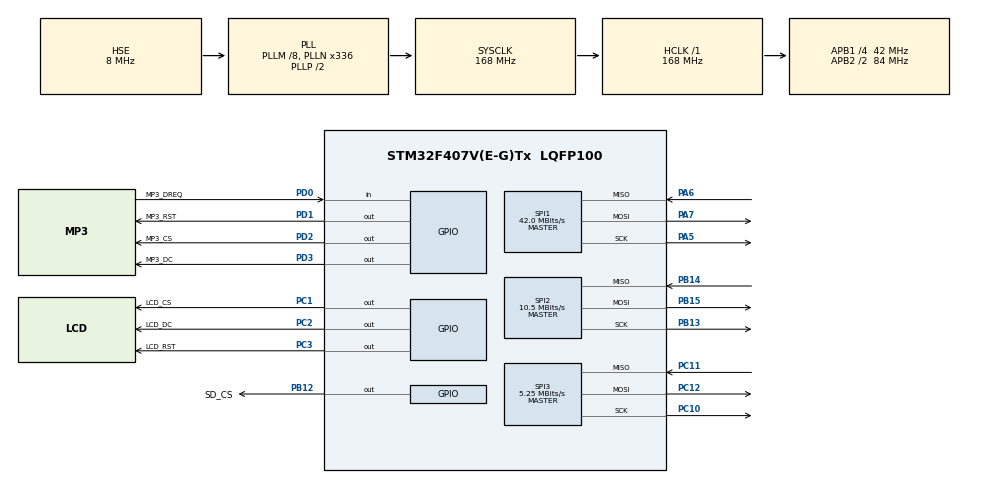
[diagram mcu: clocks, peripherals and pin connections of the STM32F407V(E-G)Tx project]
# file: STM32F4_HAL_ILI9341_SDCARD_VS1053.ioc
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Dma.Request0=SPI1_TX
Dma.SPI1_TX.0.Direction=DMA_MEMORY_TO_PERIPH
Dma.SPI1_TX.0.FIFOMode=DMA_FIFOMODE_DISABLE
Dma.SPI1_TX.0.Instance=DMA2_Stream3
Dma.SPI1_TX.0.MemDataAlignment=DMA_MDATAALIGN_BYTE
Dma.SPI1_TX.0.MemInc=DMA_MINC_ENABLE
Dma.SPI1_TX.0.Mode=DMA_NORMAL
Dma.SPI1_TX.0.PeriphDataAlignment=DMA_PDATAALIGN_BYTE
Dma.SPI1_TX.0.PeriphInc=DMA_PINC_DISABLE
Dma.SPI1_TX.0.Priority=DMA_PRIORITY_LOW
FATFS._CODE_PAGE=949
FATFS._MAX_SS=4096
FATFS._USE_LFN=1
Mcu.Family=STM32F4
Mcu.Name=STM32F407V(E-G)Tx
Mcu.Package=LQFP100
NVIC.DMA2_Stream3_IRQn=true\:0\:0\:false\:false\:true\:false
NVIC.PriorityGroup=NVIC_PRIORITYGROUP_0
NVIC.SPI1_IRQn=true\:0\:0\:false\:false\:true\:true
PA5.Mode=Full_Duplex_Master
PA5.Signal=SPI1_SCK
PA6.Mode=Full_Duplex_Master
PA6.Signal=SPI1_MISO
PA7.Mode=Full_Duplex_Master
PA7.Signal=SPI1_MOSI
PB12.GPIO_Label=SD_CS
PB12.Signal=GPIO_Output
PB13.Mode=Full_Duplex_Master
PB13.Signal=SPI2_SCK
PB14.Mode=Full_Duplex_Master
PB14.Signal=SPI2_MISO
PB15.Mode=Full_Duplex_Master
PB15.Signal=SPI2_MOSI
PC1.GPIO_Label=LCD_CS
PC1.PinState=GPIO_PIN_RESET
PC1.Signal=GPIO_Output
PC10.Mode=Full_Duplex_Master
PC10.Signal=SPI3_SCK
PC11.Mode=Full_Duplex_Master
PC11.Signal=SPI3_MISO
PC12.Mode=Full_Duplex_Master
PC12.Signal=SPI3_MOSI
PC2.GPIO_Label=LCD_DC
PC2.Signal=GPIO_Output
PC3.GPIO_Label=LCD_RST
PC3.Signal=GPIO_Output
PD0.GPIO_Label=MP3_DREQ
PD0.GPIO_PuPd=GPIO_NOPULL
PD0.Signal=GPIO_Input
PD1.GPIO_Label=MP3_RST
PD1.Signal=GPIO_Output
PD2.GPIO_Label=MP3_CS
PD2.Signal=GPIO_Output
PD3.GPIO_Label=MP3_DC
PD3.Signal=GPIO_Output
PH0-OSC_IN.Mode=HSE-External-Oscillator
PH0-OSC_IN.Signal=RCC_OSC_IN
PH1-OSC_OUT.Mode=HSE-External-Oscillator
PH1-OSC_OUT.Signal=RCC_OSC_OUT
ProjectManager.HeapSize=0x200
ProjectManager.StackSize=0x800
ProjectManager.TargetToolchain=TrueSTUDIO
RCC.48MHZClocksFreq_Value=48000000
RCC.AHBFreq_Value=168000000
RCC.APB1CLKDivider=RCC_HCLK_DIV4
RCC.APB1Freq_Value=42000000
RCC.APB1TimFreq_Value=84000000
RCC.APB2CLKDivider=RCC_HCLK_DIV2
RCC.APB2Freq_Value=84000000
RCC.APB2TimFreq_Value=168000000
RCC.CortexFreq_Value=168000000
RCC.HCLKFreq_Value=168000000
RCC.HSE_VALUE=8000000
RCC.HSI_VALUE=16000000
RCC.LSE_VALUE=32768
RCC.PLLM=8
RCC.PLLN=336
RCC.PLLQ=7
RCC.PLLSourceVirtual=RCC_PLLSOURCE_HSE
RCC.SYSCLKFreq_VALUE=168000000
RCC.SYSCLKSource=RCC_SYSCLKSOURCE_PLLCLK
RCC.VCOOutputFreq_Value=336000000
SPI1.CalculateBaudRate=42.0 MBits/s
SPI1.Direction=SPI_DIRECTION_2LINES
SPI1.Mode=SPI_MODE_MASTER
SPI1.VirtualType=VM_MASTER
SPI2.BaudRatePrescaler=SPI_BAUDRATEPRESCALER_4
SPI2.CalculateBaudRate=10.5 MBits/s
SPI2.Direction=SPI_DIRECTION_2LINES
SPI2.Mode=SPI_MODE_MASTER
SPI2.VirtualType=VM_MASTER
SPI3.BaudRatePrescaler=SPI_BAUDRATEPRESCALER_8
SPI3.CalculateBaudRate=5.25 MBits/s
SPI3.Direction=SPI_DIRECTION_2LINES
SPI3.Mode=SPI_MODE_MASTER
SPI3.VirtualType=VM_MASTER
VP_FATFS_VS_Generic.Mode=User_defined
board=STM32F4DISCOVERY

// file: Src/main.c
/**
  ******************************************************************************
  * @file           : main.c
  * @brief          : Main program body
  ******************************************************************************
  * This notice applies to any and all portions of this file
  * that are not between comment pairs USER CODE BEGIN and
  * USER CODE END. Other portions of this file, whether
  * inserted by the user or by software development tools
  * are owned by their respective copyright owners.
  *
  * Copyright (c) 2019 STMicroelectronics International N.V.
  * All rights reserved.
  *
  * Redistribution and use in source and binary forms, with or without
  * modification, are permitted, provided that the following conditions are met:
  *
  * 1. Redistribution of source code must retain the above copyright notice,
  *    this list of conditions and the following disclaimer.
  * 2. Redistributions in binary form must reproduce the above copyright notice,
  *    this list of conditions and the following disclaimer in the documentation
  *    and/or other materials provided with the distribution.
  * 3. Neither the name of STMicroelectronics nor the names of other
  *    contributors to this software may be used to endorse or promote products
  *    derived from this software without specific written permission.
  * 4. This software, including modifications and/or derivative works of this
  *    software, must execute solely and exclusively on microcontroller or
  *    microprocessor devices manufactured by or for STMicroelectronics.
  * 5. Redistribution and use of this software other than as permitted under
  *    this license is void and will automatically terminate your rights under
  *    this license.
  *
  * THIS SOFTWARE IS PROVIDED BY STMICROELECTRONICS AND CONTRIBUTORS "AS IS"
  * AND ANY EXPRESS, IMPLIED OR STATUTORY WARRANTIES, INCLUDING, BUT NOT
  * LIMITED TO, THE IMPLIED WARRANTIES OF MERCHANTABILITY, FITNESS FOR A
  * PARTICULAR PURPOSE AND NON-INFRINGEMENT OF THIRD PARTY INTELLECTUAL PROPERTY
  * RIGHTS ARE DISCLAIMED TO THE FULLEST EXTENT PERMITTED BY LAW. IN NO EVENT
  * SHALL STMICROELECTRONICS OR CONTRIBUTORS BE LIABLE FOR ANY DIRECT, INDIRECT,
  * INCIDENTAL, SPECIAL, EXEMPLARY, OR CONSEQUENTIAL DAMAGES (INCLUDING, BUT NOT
  * LIMITED TO, PROCUREMENT OF SUBSTITUTE GOODS OR SERVICES; LOSS OF USE, DATA,
  * OR PROFITS; OR BUSINESS INTERRUPTION) HOWEVER CAUSED AND ON ANY THEORY OF
  * LIABILITY, WHETHER IN CONTRACT, STRICT LIABILITY, OR TORT (INCLUDING
  * NEGLIGENCE OR OTHERWISE) ARISING IN ANY WAY OUT OF THE USE OF THIS SOFTWARE,
  * EVEN IF ADVISED OF THE POSSIBILITY OF SUCH DAMAGE.
  *
  ******************************************************************************
  */
#include "main.h"
#include "stm32f4xx_hal.h"
#include "fatfs.h"

/* USER CODE BEGIN Includes */
#include "ILI9341_STM32_Driver.h"
#include "ILI9341_GFX.h"
#include "MP3_Player.h"

/* USER CODE END Includes */

SPI_HandleTypeDef hspi1;
SPI_HandleTypeDef hspi2;
SPI_HandleTypeDef hspi3;
DMA_HandleTypeDef hdma_spi1_tx;

/* USER CODE BEGIN PV */
/* Private variables ---------------------------------------------------------*/

/* USER CODE END PV */

void SystemClock_Config(void);
static void MX_GPIO_Init(void);
static void MX_DMA_Init(void);
static void MX_SPI1_Init(void);
static void MX_SPI2_Init(void);
static void MX_SPI3_Init(void);

/* USER CODE BEGIN PFP */
/* Private function prototypes -----------------------------------------------*/

/* USER CODE END PFP */

int main(void)
{

  /* MCU Configuration----------------------------------------------------------*/

  /* Reset of all peripherals, Initializes the Flash interface and the Systick. */
  HAL_Init();

  /* Configure the system clock */
  SystemClock_Config();

  /* Initialize all configured peripherals */
  MX_GPIO_Init();
  MX_DMA_Init();
  MX_SPI1_Init();
  MX_SPI2_Init();
  MX_FATFS_Init();
  MX_SPI3_Init();
  /* USER CODE BEGIN 2 */
	/* Wait time to power up */
	ILI9341_Init();
	ILI9341_FillScreen(WHITE);
	ILI9341_SetRotation(SCREEN_HORIZONTAL_2);

	MP3_Init();
	MP3_Play("track001.mp3");

  /* USER CODE END 2 */

  /* Infinite loop */
	while (1)
	{

	}

}

void SystemClock_Config(void)
{

  RCC_OscInitTypeDef RCC_OscInitStruct;
  RCC_ClkInitTypeDef RCC_ClkInitStruct;

    /**Configure the main internal regulator output voltage
    */
  __HAL_RCC_PWR_CLK_ENABLE();

  __HAL_PWR_VOLTAGESCALING_CONFIG(PWR_REGULATOR_VOLTAGE_SCALE1);

    /**Initializes the CPU, AHB and APB busses clocks
    */
  RCC_OscInitStruct.OscillatorType = RCC_OSCILLATORTYPE_HSE;
  RCC_OscInitStruct.HSEState = RCC_HSE_ON;
  RCC_OscInitStruct.PLL.PLLState = RCC_PLL_ON;
  RCC_OscInitStruct.PLL.PLLSource = RCC_PLLSOURCE_HSE;
  RCC_OscInitStruct.PLL.PLLM = 8;
  RCC_OscInitStruct.PLL.PLLN = 336;
  RCC_OscInitStruct.PLL.PLLP = RCC_PLLP_DIV2;
  RCC_OscInitStruct.PLL.PLLQ = 7;
  if (HAL_RCC_OscConfig(&RCC_OscInitStruct) != HAL_OK)
  {
    _Error_Handler(__FILE__, __LINE__);
  }

    /**Initializes the CPU, AHB and APB busses clocks
    */
  RCC_ClkInitStruct.ClockType = RCC_CLOCKTYPE_HCLK|RCC_CLOCKTYPE_SYSCLK
                              |RCC_CLOCKTYPE_PCLK1|RCC_CLOCKTYPE_PCLK2;
  RCC_ClkInitStruct.SYSCLKSource = RCC_SYSCLKSOURCE_PLLCLK;
  RCC_ClkInitStruct.AHBCLKDivider = RCC_SYSCLK_DIV1;
  RCC_ClkInitStruct.APB1CLKDivider = RCC_HCLK_DIV4;
  RCC_ClkInitStruct.APB2CLKDivider = RCC_HCLK_DIV2;

  if (HAL_RCC_ClockConfig(&RCC_ClkInitStruct, FLASH_LATENCY_5) != HAL_OK)
  {
    _Error_Handler(__FILE__, __LINE__);
  }

    /**Configure the Systick interrupt time
    */
  HAL_SYSTICK_Config(HAL_RCC_GetHCLKFreq()/1000);

    /**Configure the Systick
    */
  HAL_SYSTICK_CLKSourceConfig(SYSTICK_CLKSOURCE_HCLK);

  /* SysTick_IRQn interrupt configuration */
  HAL_NVIC_SetPriority(SysTick_IRQn, 0, 0);
}

/* SPI1 init function */
static void MX_SPI1_Init(void)
{

  /* SPI1 parameter configuration*/
  hspi1.Instance = SPI1;
  hspi1.Init.Mode = SPI_MODE_MASTER;
  hspi1.Init.Direction = SPI_DIRECTION_2LINES;
  hspi1.Init.DataSize = SPI_DATASIZE_8BIT;
  hspi1.Init.CLKPolarity = SPI_POLARITY_LOW;
  hspi1.Init.CLKPhase = SPI_PHASE_1EDGE;
  hspi1.Init.NSS = SPI_NSS_SOFT;
  hspi1.Init.BaudRatePrescaler = SPI_BAUDRATEPRESCALER_2;
  hspi1.Init.FirstBit = SPI_FIRSTBIT_MSB;
  hspi1.Init.TIMode = SPI_TIMODE_DISABLE;
  hspi1.Init.CRCCalculation = SPI_CRCCALCULATION_DISABLE;
  hspi1.Init.CRCPolynomial = 10;
  if (HAL_SPI_Init(&hspi1) != HAL_OK)
  {
    _Error_Handler(__FILE__, __LINE__);
  }

}

/* SPI2 init function */
static void MX_SPI2_Init(void)
{

  /* SPI2 parameter configuration*/
  hspi2.Instance = SPI2;
  hspi2.Init.Mode = SPI_MODE_MASTER;
  hspi2.Init.Direction = SPI_DIRECTION_2LINES;
  hspi2.Init.DataSize = SPI_DATASIZE_8BIT;
  hspi2.Init.CLKPolarity = SPI_POLARITY_LOW;
  hspi2.Init.CLKPhase = SPI_PHASE_1EDGE;
  hspi2.Init.NSS = SPI_NSS_SOFT;
  hspi2.Init.BaudRatePrescaler = SPI_BAUDRATEPRESCALER_4;
  hspi2.Init.FirstBit = SPI_FIRSTBIT_MSB;
  hspi2.Init.TIMode = SPI_TIMODE_DISABLE;
  hspi2.Init.CRCCalculation = SPI_CRCCALCULATION_DISABLE;
  hspi2.Init.CRCPolynomial = 10;
  if (HAL_SPI_Init(&hspi2) != HAL_OK)
  {
    _Error_Handler(__FILE__, __LINE__);
  }

}

/* SPI3 init function */
static void MX_SPI3_Init(void)
{

  /* SPI3 parameter configuration*/
  hspi3.Instance = SPI3;
  hspi3.Init.Mode = SPI_MODE_MASTER;
  hspi3.Init.Direction = SPI_DIRECTION_2LINES;
  hspi3.Init.DataSize = SPI_DATASIZE_8BIT;
  hspi3.Init.CLKPolarity = SPI_POLARITY_LOW;
  hspi3.Init.CLKPhase = SPI_PHASE_1EDGE;
  hspi3.Init.NSS = SPI_NSS_SOFT;
  hspi3.Init.BaudRatePrescaler = SPI_BAUDRATEPRESCALER_8;
  hspi3.Init.FirstBit = SPI_FIRSTBIT_MSB;
  hspi3.Init.TIMode = SPI_TIMODE_DISABLE;
  hspi3.Init.CRCCalculation = SPI_CRCCALCULATION_DISABLE;
  hspi3.Init.CRCPolynomial = 10;
  if (HAL_SPI_Init(&hspi3) != HAL_OK)
  {
    _Error_Handler(__FILE__, __LINE__);
  }

}

static void MX_DMA_Init(void)
{
  /* DMA controller clock enable */
  __HAL_RCC_DMA2_CLK_ENABLE();

  /* DMA interrupt init */
  /* DMA2_Stream3_IRQn interrupt configuration */
  HAL_NVIC_SetPriority(DMA2_Stream3_IRQn, 0, 0);
  HAL_NVIC_EnableIRQ(DMA2_Stream3_IRQn);

}

/** Configure pins as
        * Analog
        * Input
        * Output
        * EVENT_OUT
        * EXTI
*/
static void MX_GPIO_Init(void)
{

  GPIO_InitTypeDef GPIO_InitStruct;

  /* GPIO Ports Clock Enable */
  __HAL_RCC_GPIOH_CLK_ENABLE();
  __HAL_RCC_GPIOC_CLK_ENABLE();
  __HAL_RCC_GPIOA_CLK_ENABLE();
  __HAL_RCC_GPIOB_CLK_ENABLE();
  __HAL_RCC_GPIOD_CLK_ENABLE();

  /*Configure GPIO pin Output Level */
  HAL_GPIO_WritePin(GPIOC, LCD_CS_Pin|LCD_DC_Pin|LCD_RST_Pin, GPIO_PIN_RESET);

  /*Configure GPIO pin Output Level */
  HAL_GPIO_WritePin(SD_CS_GPIO_Port, SD_CS_Pin, GPIO_PIN_RESET);

  /*Configure GPIO pin Output Level */
  HAL_GPIO_WritePin(GPIOD, MP3_RST_Pin|MP3_CS_Pin|MP3_DC_Pin, GPIO_PIN_RESET);

  /*Configure GPIO pins : LCD_CS_Pin LCD_DC_Pin LCD_RST_Pin */
  GPIO_InitStruct.Pin = LCD_CS_Pin|LCD_DC_Pin|LCD_RST_Pin;
  GPIO_InitStruct.Mode = GPIO_MODE_OUTPUT_PP;
  GPIO_InitStruct.Pull = GPIO_NOPULL;
  GPIO_InitStruct.Speed = GPIO_SPEED_FREQ_LOW;
  HAL_GPIO_Init(GPIOC, &GPIO_InitStruct);

  /*Configure GPIO pin : SD_CS_Pin */
  GPIO_InitStruct.Pin = SD_CS_Pin;
  GPIO_InitStruct.Mode = GPIO_MODE_OUTPUT_PP;
  GPIO_InitStruct.Pull = GPIO_NOPULL;
  GPIO_InitStruct.Speed = GPIO_SPEED_FREQ_LOW;
  HAL_GPIO_Init(SD_CS_GPIO_Port, &GPIO_InitStruct);

  /*Configure GPIO pin : MP3_DREQ_Pin */
  GPIO_InitStruct.Pin = MP3_DREQ_Pin;
  GPIO_InitStruct.Mode = GPIO_MODE_INPUT;
  GPIO_InitStruct.Pull = GPIO_NOPULL;
  HAL_GPIO_Init(MP3_DREQ_GPIO_Port, &GPIO_InitStruct);

  /*Configure GPIO pins : MP3_RST_Pin MP3_CS_Pin MP3_DC_Pin */
  GPIO_InitStruct.Pin = MP3_RST_Pin|MP3_CS_Pin|MP3_DC_Pin;
  GPIO_InitStruct.Mode = GPIO_MODE_OUTPUT_PP;
  GPIO_InitStruct.Pull = GPIO_NOPULL;
  GPIO_InitStruct.Speed = GPIO_SPEED_FREQ_LOW;
  HAL_GPIO_Init(GPIOD, &GPIO_InitStruct);

}

void _Error_Handler(char *file, int line)
{
	while(1)
	{
	}
}

/************************ (C) COPYRIGHT STMicroelectronics *****END OF FILE****/
